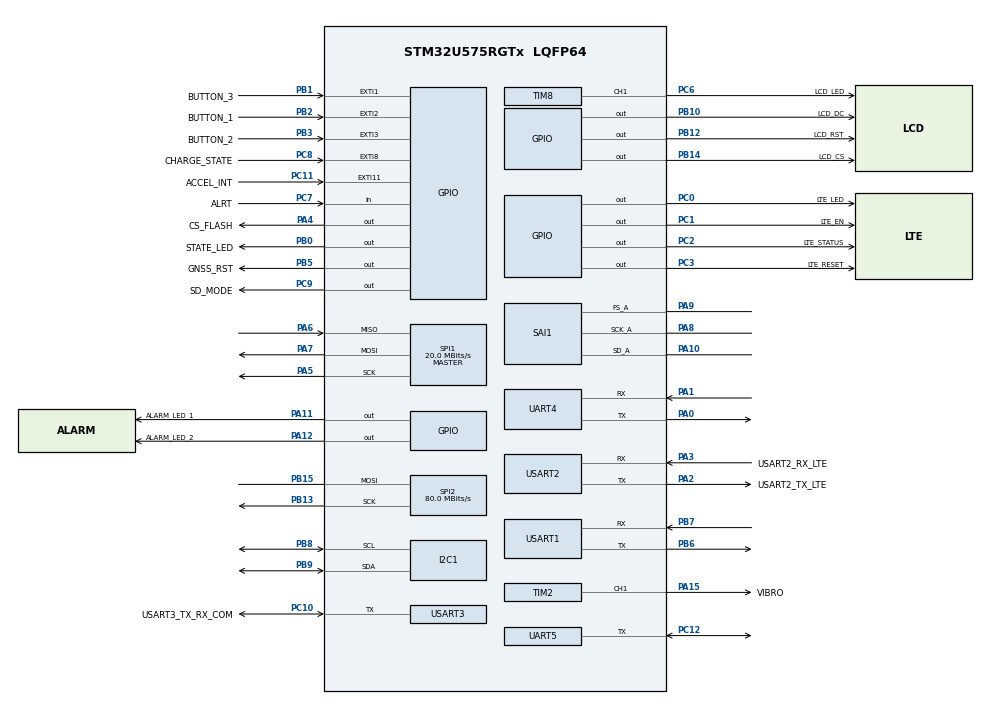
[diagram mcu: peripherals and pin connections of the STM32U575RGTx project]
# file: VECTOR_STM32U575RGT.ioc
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CORTEX_M33_NS.userName=CORTEX_M33
GPDMA1.CIRCULARMODE_GPDMACH11=ENABLE
GPDMA1.DATAEXCHANGE_GPDMACH10-SIMPLEREQUEST_GPDMACH10=DMA_EXCHANGE_DEST_BYTE|DMA_EXCHANGE_DEST_HALFWORD|DMA_EXCHANGE_SRC_BYTE
GPDMA1.DATAEXCHANGE_GPDMACH11-SIMPLEREQUEST_GPDMACH11=DMA_EXCHANGE_DEST_HALFWORD
GPDMA1.DATAEXCHANGE_GPDMACH9-SIMPLEREQUEST_GPDMACH9=DMA_EXCHANGE_DEST_BYTE|DMA_EXCHANGE_DEST_HALFWORD|DMA_EXCHANGE_SRC_BYTE
GPDMA1.DESTDATAWIDTH_GPDMACH11=DMA_DEST_DATAWIDTH_HALFWORD
GPDMA1.DESTINC_GPDMACH10=DMA_DINC_INCREMENTED
GPDMA1.DESTINC_GPDMACH8=DMA_DINC_FIXED
GPDMA1.DIRECTION_GPDMACH11=DMA_MEMORY_TO_PERIPH
GPDMA1.DIRECTION_GPDMACH8=DMA_MEMORY_TO_PERIPH
GPDMA1.DIRECTION_GPDMACH9=DMA_MEMORY_TO_PERIPH
GPDMA1.DMAHANDLE_GPDMACH11=hdmatx
GPDMA1.IPHANDLE_GPDMACH10-SIMPLEREQUEST_GPDMACH10=__NULL
GPDMA1.IPHANDLE_GPDMACH11-SIMPLEREQUEST_GPDMACH11=__NULL
GPDMA1.IPHANDLE_GPDMACH8-SIMPLEREQUEST_GPDMACH8=__NULL
GPDMA1.IPHANDLE_GPDMACH9-SIMPLEREQUEST_GPDMACH9=__NULL
GPDMA1.REQUEST_GPDMACH10=GPDMA1_REQUEST_SPI1_RX
GPDMA1.REQUEST_GPDMACH11=GPDMA1_REQUEST_SAI1_A
GPDMA1.REQUEST_GPDMACH8=GPDMA1_REQUEST_SPI2_TX
GPDMA1.REQUEST_GPDMACH9=GPDMA1_REQUEST_SPI1_TX
GPDMA1.SRCDATAWIDTH_GPDMACH11=DMA_SRC_DATAWIDTH_HALFWORD
GPDMA1.SRCINC_GPDMACH11=DMA_SINC_INCREMENTED
GPDMA1.SRCINC_GPDMACH8=DMA_SINC_INCREMENTED
GPDMA1.SRCINC_GPDMACH9=DMA_SINC_INCREMENTED
I2C1.Timing=0x30909DEC
Mcu.Family=STM32U5
Mcu.Name=STM32U575RGTx
Mcu.Package=LQFP64
NVIC.EXTI11_IRQn=true\:0\:0\:false\:false\:true\:false\:true\:true\:true
NVIC.EXTI1_IRQn=true\:0\:0\:false\:false\:true\:false\:true\:true\:true
NVIC.EXTI2_IRQn=true\:0\:0\:false\:false\:true\:false\:true\:true\:true
NVIC.EXTI3_IRQn=true\:0\:0\:false\:false\:true\:false\:true\:true\:true
NVIC.EXTI8_IRQn=true\:0\:0\:false\:false\:true\:false\:true\:true\:true
NVIC.GPDMA1_Channel10_IRQn=true\:0\:0\:false\:false\:true\:true\:false\:true\:true
NVIC.GPDMA1_Channel11_IRQn=true\:0\:0\:false\:false\:true\:true\:false\:true\:true
NVIC.GPDMA1_Channel8_IRQn=true\:0\:0\:false\:false\:true\:true\:false\:true\:true
NVIC.GPDMA1_Channel9_IRQn=true\:0\:0\:false\:false\:true\:true\:false\:true\:true
NVIC.I2C1_ER_IRQn=true\:0\:0\:false\:false\:true\:false\:true\:true\:true
NVIC.PriorityGroup=NVIC_PRIORITYGROUP_4
NVIC.RTC_IRQn=true\:0\:0\:false\:false\:true\:false\:true\:true\:true
NVIC.SPI1_IRQn=true\:0\:0\:false\:false\:true\:false\:false\:true\:true
NVIC.SPI2_IRQn=true\:0\:0\:false\:false\:true\:false\:false\:true\:true
NVIC.TIM3_IRQn=true\:2\:0\:true\:false\:true\:false\:true\:true\:true
NVIC.TIM6_IRQn=true\:10\:0\:true\:false\:true\:false\:false\:true\:true
NVIC.TimeBase=TIM6_IRQn
NVIC.TimeBaseIP=TIM6
NVIC.UART4_IRQn=true\:0\:0\:false\:false\:true\:false\:true\:true\:true
NVIC.UART5_IRQn=true\:0\:0\:false\:false\:true\:false\:true\:true\:true
NVIC.USART1_IRQn=true\:0\:0\:false\:false\:true\:false\:true\:true\:true
NVIC.USART2_IRQn=true\:1\:0\:true\:false\:true\:false\:true\:true\:true
NVIC.USART3_IRQn=true\:0\:0\:false\:false\:true\:false\:true\:true\:true
PA0.Mode=Asynchronous
PA0.Signal=UART4_TX
PA1.Mode=Asynchronous
PA1.Signal=UART4_RX
PA10.Mode=SAI_A_Master
PA10.PinAttribute=Free
PA10.Signal=SAI1_SD_A
PA11.GPIO_Label=ALARM_LED_1
PA11.PinAttribute=Free
PA11.Signal=GPIO_Output
PA12.GPIO_Label=ALARM_LED_2
PA12.PinAttribute=Free
PA12.Signal=GPIO_Output
PA13\ (JTMS/SWDIO).Mode=Serial_Wire
PA13\ (JTMS/SWDIO).PinAttribute=Free
PA13\ (JTMS/SWDIO).Signal=DEBUG_JTMS-SWDIO
PA14\ (JTCK/SWCLK).Mode=Serial_Wire
PA14\ (JTCK/SWCLK).PinAttribute=Free
PA14\ (JTCK/SWCLK).Signal=DEBUG_JTCK-SWCLK
PA15\ (JTDI).GPIO_Label=VIBRO
PA15\ (JTDI).PinAttribute=Free
PA15\ (JTDI).Signal=S_TIM2_CH1
PA2.GPIO_Label=USART2_TX_LTE
PA2.Mode=Asynchronous
PA2.PinAttribute=Free
PA2.Signal=USART2_TX
PA3.GPIO_Label=USART2_RX_LTE
PA3.Mode=Asynchronous
PA3.PinAttribute=Free
PA3.Signal=USART2_RX
PA4.GPIO_Label=CS_FLASH
PA4.PinAttribute=Free
PA4.Signal=GPIO_Output
PA5.GPIO_Speed=GPIO_SPEED_FREQ_VERY_HIGH
PA5.Mode=Full_Duplex_Master
PA5.PinAttribute=Free
PA5.Signal=SPI1_SCK
PA6.GPIO_Speed=GPIO_SPEED_FREQ_VERY_HIGH
PA6.Mode=Full_Duplex_Master
PA6.PinAttribute=Free
PA6.Signal=SPI1_MISO
PA7.GPIO_Speed=GPIO_SPEED_FREQ_VERY_HIGH
PA7.Mode=Full_Duplex_Master
PA7.PinAttribute=Free
PA7.Signal=SPI1_MOSI
PA8.Mode=SAI_A_Master
PA8.PinAttribute=Free
PA8.Signal=SAI1_SCK_A
PA9.Mode=SAI_A_Master
PA9.PinAttribute=Free
PA9.Signal=SAI1_FS_A
PB0.GPIO_Label=STATE_LED
PB0.PinAttribute=Free
PB0.Signal=GPIO_Output
PB1.GPIO_Label=BUTTON_3
PB1.GPIO_ModeDefaultEXTI=GPIO_MODE_IT_RISING_FALLING
PB1.GPIO_PuPd=GPIO_PULLUP
PB1.PinAttribute=Free
PB1.Signal=GPXTI1
PB10.GPIO_Label=LCD_DC
PB10.PinAttribute=Free
PB10.Signal=GPIO_Output
PB12.GPIO_Label=LCD_RST
PB12.PinAttribute=Free
PB12.Signal=GPIO_Output
PB13.GPIO_Speed=GPIO_SPEED_FREQ_HIGH
PB13.Mode=Simplex_Bidirectional_Master
PB13.PinAttribute=Free
PB13.Signal=SPI2_SCK
PB14.GPIO_Label=LCD_CS
PB14.PinAttribute=Free
PB14.Signal=GPIO_Output
PB15.GPIO_Speed=GPIO_SPEED_FREQ_HIGH
PB15.Mode=Simplex_Bidirectional_Master
PB15.PinAttribute=Free
PB15.Signal=SPI2_MOSI
PB2.GPIO_Label=BUTTON_1
PB2.GPIO_ModeDefaultEXTI=GPIO_MODE_IT_RISING_FALLING
PB2.GPIO_PuPd=GPIO_PULLUP
PB2.PinAttribute=Free
PB2.Signal=GPXTI2
PB3\ (JTDO/TRACESWO).GPIO_Label=BUTTON_2
PB3\ (JTDO/TRACESWO).GPIO_ModeDefaultEXTI=GPIO_MODE_IT_RISING_FALLING
PB3\ (JTDO/TRACESWO).GPIO_PuPd=GPIO_PULLUP
PB3\ (JTDO/TRACESWO).PinAttribute=Free
PB3\ (JTDO/TRACESWO).Signal=GPXTI3
PB5.GPIO_Label=GNSS_RST
PB5.PinState=GPIO_PIN_SET
PB5.Signal=GPIO_Output
PB6.Mode=Asynchronous
PB6.PinAttribute=Free
PB6.Signal=USART1_TX
PB7.Mode=Asynchronous
PB7.PinAttribute=Free
PB7.Signal=USART1_RX
PB8.Mode=I2C
PB8.PinAttribute=Free
PB8.Signal=I2C1_SCL
PB9.Mode=I2C
PB9.PinAttribute=Free
PB9.Signal=I2C1_SDA
PC0.GPIO_Label=LTE_LED
PC0.PinAttribute=Free
PC0.Signal=GPIO_Output
PC1.GPIO_Label=LTE_EN
PC1.PinAttribute=Free
PC1.Signal=GPIO_Output
PC10.GPIO_Label=USART3_TX_RX_COM
PC10.Mode=Half_duplex(single_wire_mode)
PC10.PinAttribute=Free
PC10.Signal=USART3_TX
PC11.GPIO_Label=ACCEL_INT
PC11.GPIO_ModeDefaultEXTI=GPIO_MODE_IT_RISING_FALLING
PC11.GPIO_PuPd=GPIO_PULLDOWN
PC11.Signal=GPXTI11
PC12.GPIO_PuPd=GPIO_PULLUP
PC12.Mode=Half_duplex(single_wire_mode)
PC12.Signal=UART5_TX
PC14-OSC32_IN\ (PC14).Mode=LSE-External-Oscillator
PC14-OSC32_IN\ (PC14).PinAttribute=Free
PC14-OSC32_IN\ (PC14).Signal=RCC_OSC32_IN
PC15-OSC32_OUT\ (PC15).Mode=LSE-External-Oscillator
PC15-OSC32_OUT\ (PC15).PinAttribute=Free
PC15-OSC32_OUT\ (PC15).Signal=RCC_OSC32_OUT
PC2.GPIO_Label=LTE_STATUS
PC2.PinAttribute=Free
PC2.Signal=GPIO_Output
PC3.GPIO_Label=LTE_RESET
PC3.PinAttribute=Free
PC3.PinState=GPIO_PIN_RESET
PC3.Signal=GPIO_Output
PC6.GPIO_Label=LCD_LED
PC6.Signal=S_TIM8_CH1
PC7.GPIO_Label=ALRT
PC7.PinAttribute=Free
PC7.Signal=GPIO_Input
PC8.GPIO_Label=CHARGE_STATE
PC8.GPIO_ModeDefaultEXTI=GPIO_MODE_IT_RISING_FALLING
PC8.PinAttribute=Free
PC8.Signal=GPXTI8
PC9.GPIO_Label=SD_MODE
PC9.PinAttribute=Free
PC9.Signal=GPIO_Output
PH0-OSC_IN\ (PH0).Mode=HSE-External-Oscillator
PH0-OSC_IN\ (PH0).PinAttribute=Free
PH0-OSC_IN\ (PH0).Signal=RCC_OSC_IN
PH1-OSC_OUT\ (PH1).Mode=HSE-External-Oscillator
PH1-OSC_OUT\ (PH1).PinAttribute=Free
PH1-OSC_OUT\ (PH1).Signal=RCC_OSC_OUT
ProjectManager.HeapSize=0x200
ProjectManager.StackSize=0x400
ProjectManager.TargetToolchain=STM32CubeIDE
RCC.ADCFreq_Value=16000000
RCC.AHBFreq_Value=160000000
RCC.APB1Freq_Value=160000000
RCC.APB1TimFreq_Value=160000000
RCC.APB2Freq_Value=160000000
RCC.APB2TimFreq_Value=160000000
RCC.APB3Freq_Value=160000000
RCC.CortexFreq_Value=160000000
RCC.EPOD_VALUE=8000000
RCC.HCLKFreq_Value=160000000
RCC.HSE_VALUE=8000000
RCC.HSI48_VALUE=48000000
RCC.HSI_VALUE=16000000
RCC.LSIDIV_VALUE=32000
RCC.MSIKERON=true
RCC.MSI_VALUE=4000000
RCC.PLL1R=1
RCC.PLL2FRACN=0
RCC.PLL2M=3
RCC.PLL2N=8
RCC.PLL2P=1
RCC.PLL3FRACN=3671
RCC.PLL3M=2
RCC.PLL3N=56
RCC.PLL3P=20
RCC.PLL3Source=RCC_PLLSOURCE_HSE
RCC.PLLFRACN=0
RCC.PLLN=20
RCC.PLLSourceVirtual=RCC_PLLSOURCE_HSE
RCC.RTCClockSelection=RCC_RTCCLKSOURCE_LSE
RCC.SAI1CLockSelection=RCC_SAI1CLKSOURCE_PLL3
RCC.SYSCLKFreq_VALUE=160000000
RCC.SYSCLKSource=RCC_SYSCLKSOURCE_PLLCLK
RCC.USBFreq_Value=48000000
RCC.VCOOutputFreq_Value=160000000
RTC.WakeUpClock-WakeUp=RTC_WAKEUPCLOCK_CK_SPRE_16BITS
SAI1.AudioFrequency-SAI_A_Master=SAI_AUDIO_FREQUENCY_44K
SAI1.BasicProtocol-SAI_A_Master=SAI_I2S_STANDARD
SAI1.BasicSlotNumber-SAI_A_Master=2
SAI1.ErrorAudioFreq-SAI_A_Master=0.0 %
SAI1.FIFOThreshold-SAI_A_Master=SAI_FIFOTHRESHOLD_1QF
SAI1.InitProtocol-SAI_A_Master=Enable
SAI1.Instance-SAI_A_Master=SAI$Index_Block_A
SAI1.MckOutput-SAI_A_Master=SAI_MCK_OUTPUT_DISABLE
SAI1.MonoStereoMode-SAI_A_Master=SAI_MONOMODE
SAI1.RealAudioFreq-SAI_A_Master=44.1 KHz
SAI1.VirtualMode-SAI_A_Master=VM_MASTER
SAI1.VirtualProtocol-SAI_A_BASIC=VM_BASIC_PROTOCOL
SH.S_TIM2_CH1.0=TIM2_CH1,PWM Generation1 CH1
SH.S_TIM8_CH1.0=TIM8_CH1,PWM Generation1 CH1
SPI1.BaudRatePrescaler=SPI_BAUDRATEPRESCALER_8
SPI1.CalculateBaudRate=20.0 MBits/s
SPI1.DataSize=SPI_DATASIZE_8BIT
SPI1.Direction=SPI_DIRECTION_2LINES
SPI1.Mode=SPI_MODE_MASTER
SPI1.VirtualType=VM_MASTER
SPI2.BaudRatePrescaler=SPI_BAUDRATEPRESCALER_2
SPI2.CalculateBaudRate=80.0 MBits/s
SPI2.DataSize=SPI_DATASIZE_8BIT
SPI2.Direction=SPI_DIRECTION_1LINE
SPI2.Mode=SPI_MODE_MASTER
SPI2.VirtualType=VM_MASTER
TIM2.Channel-PWM\ Generation1\ CH1=TIM_CHANNEL_1
TIM3.AutoReloadPreload=TIM_AUTORELOAD_PRELOAD_DISABLE
TIM3.PeriodNoDither=1000
TIM3.Prescaler=159
TIM8.Channel-PWM\ Generation1\ CH1=TIM_CHANNEL_1
TIM8.OCPolarity_1=TIM_OCPOLARITY_LOW
TIM8.PeriodNoDither=39
TIM8.Prescaler=159
UART4.OverSampling=UART_OVERSAMPLING_8
USART1.ClockPrescaler=PRESCALER_DIV2
USART1.OverSampling=UART_OVERSAMPLING_8
USART1.VirtualMode-Asynchronous=VM_ASYNC
USART2.ClockPrescaler=PRESCALER_DIV2
USART2.OverSampling=UART_OVERSAMPLING_8
USART2.VirtualMode-Asynchronous=VM_ASYNC
USART3.ClockPrescaler=PRESCALER_DIV1
USART3.OverSampling=UART_OVERSAMPLING_16
USART3.VirtualMode-Half_duplex(single_wire_mode)=VM_ASYNC
VP_GPDMA1_VS_GPDMACH10.Mode=SIMPLEREQUEST_GPDMACH10
VP_GPDMA1_VS_GPDMACH11.Mode=SIMPLEREQUEST_GPDMACH11
VP_GPDMA1_VS_GPDMACH8.Mode=SIMPLEREQUEST_GPDMACH8
VP_GPDMA1_VS_GPDMACH9.Mode=SIMPLEREQUEST_GPDMACH9
VP_ICACHE_VS_ICACHE.Mode=DirectMappedCache
VP_LPBAMQUEUE_VS_QUEUE.Mode=QUEUEMODE
VP_LPBAM_VS_SIG1.Mode=SmartRun
VP_LPBAM_VS_SIG4.Mode=LPDMA1
VP_MEMORYMAP_VS_MEMORYMAP.Mode=CurAppReg
VP_PWR_VS_LPOM.Mode=PowerOptimisation
VP_PWR_VS_SECSignals.Mode=Security/Privilege
VP_RTC_VS_RTC_Activate.Mode=RTC_Enabled
VP_RTC_VS_RTC_WakeUp_intern.Mode=WakeUp
VP_SAI1_VP_$IpInstance_SAIA_SAI_BASIC.Mode=SAI_A_BASIC
VP_SYS_VS_tim6.Mode=TIM6
VP_THREADX_VS_RTOSJjThreadXJjCoreJjDefault.Mode=Core_Default
VP_TIM3_VS_ClockSourceINT.Mode=Internal
board=custom

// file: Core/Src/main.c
/* USER CODE BEGIN Header */
/**
  ******************************************************************************
  * @file           : main.c
  * @brief          : Main program body
  ******************************************************************************
  * @attention
  *
  * Copyright (c) 2026 STMicroelectronics.
  * All rights reserved.
  *
  * This software is licensed under terms that can be found in the LICENSE file
  * in the root directory of this software component.
  * If no LICENSE file comes with this software, it is provided AS-IS.
  *
  ******************************************************************************
  */
/* USER CODE END Header */
#include "app_threadx.h"
#include "main.h"
#include "gpdma.h"
#include "i2c.h"
#include "icache.h"
#include "rtc.h"
#include "sai.h"
#include "spi.h"
#include "tim.h"
#include "usart.h"
#include "gpio.h"

/* USER CODE BEGIN Includes */
#include "main_vector.h"    /* CONFIG_*, Uart_Gps/Lora_Receive_Timer_Inc */
/* USER CODE END Includes */

void SystemClock_Config(void);
void PeriphCommonClock_Config(void);

int main(void)
{

  /* MCU Configuration--------------------------------------------------------*/

  /* Reset of all peripherals, Initializes the Flash interface and the Systick. */
  HAL_Init();

  /* Configure the system clock */
  SystemClock_Config();

  /* Configure the peripherals common clocks */
  PeriphCommonClock_Config();

  /* Initialize all configured peripherals */
  MX_GPIO_Init();
  MX_GPDMA1_Init();
  MX_I2C1_Init();
  MX_SAI1_Init();
  MX_SPI1_Init();
  MX_SPI2_Init();
  MX_TIM2_Init();
  MX_UART4_Init();
  MX_USART1_UART_Init();
  MX_USART3_UART_Init();
  MX_USART2_UART_Init();
  MX_ICACHE_Init();
  MX_RTC_Init();
  MX_TIM3_Init();
  MX_TIM8_Init();
  MX_UART5_Init();
  /* USER CODE BEGIN 2 */

  /* Бортовая инициализация до RTOS одним вызовом (такт SRAM4, заморозка TIM6
     под отладчиком, SD_MODE усилителя, sf_probe, audio_selftest) - живет в
     main_vector.c, см. Vector_Run_Board_Init().                            */
  Vector_Run_Board_Init();
  /* USER CODE END 2 */

  MX_ThreadX_Init();

  /* We should never get here as control is now taken by the scheduler */

  /* Infinite loop */
  while (1)
  {

  }
}

void SystemClock_Config(void)
{
  LL_FLASH_SetLatency(LL_FLASH_LATENCY_4);
  while(LL_FLASH_GetLatency()!= LL_FLASH_LATENCY_4)
  {
  }

  LL_PWR_SetRegulVoltageScaling(LL_PWR_REGU_VOLTAGE_SCALE1);
  while (LL_PWR_IsActiveFlag_VOS() == 0)
  {
  }
  LL_RCC_HSE_Enable();

   /* Wait till HSE is ready */
  while(LL_RCC_HSE_IsReady() != 1)
  {
  }

  LL_PWR_EnableBkUpAccess();
  while (LL_PWR_IsEnabledBkUpAccess () == 0U)
  {
  }

  LL_RCC_LSE_SetDriveCapability(LL_RCC_LSEDRIVE_LOW);
  LL_RCC_LSE_EnablePropagation();
  LL_RCC_LSE_Enable();

   /* Wait till LSE is ready */
  while(LL_RCC_LSE_IsReady() != 1)
  {
  }

  LL_RCC_PLL1_ConfigDomain_SYS(LL_RCC_PLL1SOURCE_HSE, 1, 20, 1);
  LL_RCC_PLL1_EnableDomain_SYS();
  LL_RCC_SetPll1EPodPrescaler(LL_RCC_PLL1MBOOST_DIV_1);
  LL_RCC_PLL1_SetVCOInputRange(LL_RCC_PLLINPUTRANGE_8_16);
  LL_RCC_PLL1_Enable();

   /* Wait till PLL is ready */
  while(LL_RCC_PLL1_IsReady() != 1)
  {
  }

   /* Intermediate AHB prescaler 2 when target frequency clock is higher than 80 MHz */
  LL_RCC_SetAHBPrescaler(LL_RCC_SYSCLK_DIV_2);

  LL_RCC_SetSysClkSource(LL_RCC_SYS_CLKSOURCE_PLL1);

   /* Wait till System clock is ready */
  while(LL_RCC_GetSysClkSource() != LL_RCC_SYS_CLKSOURCE_STATUS_PLL1)
  {
  }

  /* Insure 1us transition state at intermediate medium speed clock*/
  for (__IO uint32_t i = (160 >> 1); i !=0; i--);

  LL_RCC_SetAHBPrescaler(LL_RCC_SYSCLK_DIV_1);
  LL_RCC_SetAPB1Prescaler(LL_RCC_APB1_DIV_1);
  LL_RCC_SetAPB2Prescaler(LL_RCC_APB2_DIV_1);
  LL_RCC_SetAPB3Prescaler(LL_RCC_APB3_DIV_1);
  LL_SetSystemCoreClock(160000000);

   /* Update the time base */
  if (HAL_InitTick (TICK_INT_PRIORITY) != HAL_OK)
  {
    Error_Handler();
  }
  LL_RCC_MSIK_EnableInStopMode();
}

void PeriphCommonClock_Config(void)
{
  LL_RCC_PLL3_ConfigDomain_SAI(LL_RCC_PLL3SOURCE_HSE, 2, 56, 20);
  LL_RCC_PLL3_EnableDomain_SAI();
  LL_RCC_PLL3_SetVCOInputRange(LL_RCC_PLLINPUTRANGE_4_8);
  LL_RCC_PLL3_Enable();

   /* Wait till PLL3 is ready */
  while(LL_RCC_PLL3_IsReady() != 1)
  {
  }
  LL_RCC_PLL3FRACN_Enable();
  LL_RCC_PLL3_SetFRACN(3671);
}

/* USER CODE BEGIN 4 */
//===========================================================================================================================
/* Обслуживание таймеров прибора (Countdown_Timer, Countdown_Timer_Rtc,
   Clear_Timer_Rtc, Timer_Tick_1ms/1s) - в main_vector.c: там же экземпляры
   timer / countdown_time / countdown_time_rtc. Здесь остаются только вызовы
   из прерываний.                                                           */
/* USER CODE END 4 */

void HAL_TIM_PeriodElapsedCallback(TIM_HandleTypeDef *htim)
{
  /* USER CODE BEGIN Callback 0 */
//	if (htim->Instance == TIM6){
//		SET_TGL(ALARM_LED_1);
//	}
  /* пусто: мигалку/счётчики сюда ставить не нужно, всё ниже в hook */
  /* USER CODE END Callback 0 */
  if (htim->Instance == TIM6)
  {
    HAL_IncTick();
  }
  /* USER CODE BEGIN Callback 1 */
  else if(htim->Instance == TIM3){
	  /* TIM3 = 1 кГц: такт таймеров прибора. Всё (декремент countdown_time[],
	     флаги timer.flag_1ms/10ms/100ms/1s, счётчики кнопок, таймауты кадров
	     COM/GPS/LoRa) делает Timer_Tick_1ms() из main_vector.c.              */
	  Timer_Tick_1ms();
  }
  /* TIM6 - только тайм-база HAL (uwTick). Время потоков - тик ThreadX
     (vector_tick.h), таймеры прибора - TIM3/RTC (Timer_Tick_1ms/1s).       */
  /* USER CODE END Callback 1 */
}

void Error_Handler(void)
{
  __disable_irq();
  while (1)
  {
  }
}
